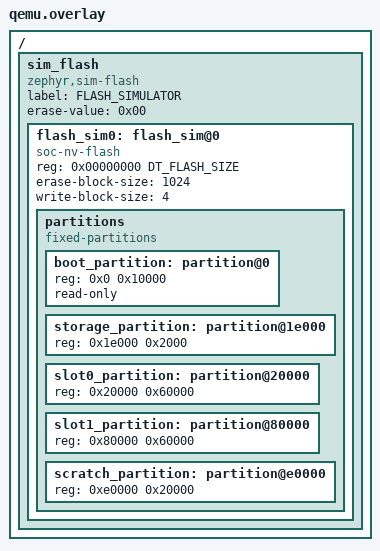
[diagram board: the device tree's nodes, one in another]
#include <mem.h>

#define DT_FLASH_SIZE		DT_SIZE_M(4)
#define DT_SRAM_SIZE		DT_SIZE_M(4)

/ {
	sim_flash {
		compatible = "zephyr,sim-flash";
		label = "FLASH_SIMULATOR";
		status = "okay";
        erase-value = <0x00>;

		#address-cells = <1>;
		#size-cells = <1>;

		flash_sim0: flash_sim@0 {
			compatible = "soc-nv-flash";

			reg = <0x00000000 DT_FLASH_SIZE>;

			erase-block-size = <1024>;
			write-block-size = <4>;

			partitions {
				compatible = "fixed-partitions";
				#address-cells = <0x1>;
				#size-cells = <0x1>;

				boot_partition: partition@0 {
					reg = <0x0 0x10000>;
					read-only;
				};
				storage_partition: partition@1e000 {
					reg = <0x1e000 0x2000>;
				};
				slot0_partition: partition@20000 {
					reg = <0x20000 0x60000>;
				};
				slot1_partition: partition@80000 {
					reg = <0x80000 0x60000>;
				};
				scratch_partition: partition@e0000 {
					reg = <0xe0000 0x20000>;
				};
			};
		};
	};
};
